# STM32H7A3xxQ register map
File version: 1.0
Registers are 32-bit, read-write, reset 0x0 unless marked. A register's access mark holds for its fields unless they carry their own. Offsets are from the block's base; [hi:lo] are bit positions; lines under a group give offsets from that group.

## DFSDM1_Filter0 — DFSDM module registers
Base 0x40017900
Same registers: DFSDM1_Filter1 0x40017980, DFSDM1_Filter2 0x40017A00, DFSDM1_Filter3 0x40017A80, DFSDM1_Filter4 0x40017B00, DFSDM1_Filter5 0x40017B80, DFSDM1_Filter6 0x40017C00, DFSDM1_Filter7 0x40017C80
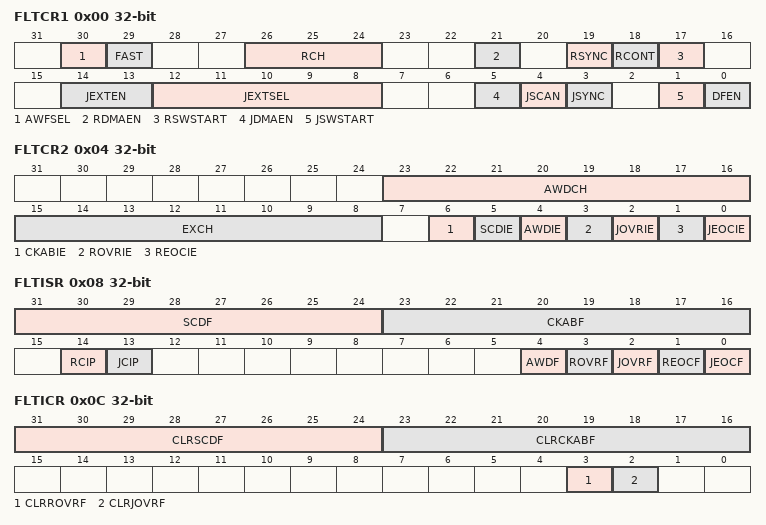
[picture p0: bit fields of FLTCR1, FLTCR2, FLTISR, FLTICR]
0x00 FLTCR1 — DFSDM control register1
  [30] AWFSEL — Analog watchdog fast mode select
  [29] FAST — Fast conversion mode selection
  [26:24] RCH — RCH[2:0] Regular channel selection
  [21] RDMAEN — DMA channel enabled to read data for the regular conversion
  [19] RSYNC — Launch regular conversion synchronously with DFSDMx
  [18] RCONT — Continuous mode selection for regular conversions
  [17] RSWSTART — Software start of a conversion on the regular channel
  [14:13] JEXTEN — JEXTEN[1:0] Trigger enable and trigger edge selection for injected conversions
  [12:8] JEXTSEL — JEXTSEL[4:0]Trigger signal selection for launching injected conversions
  [5] JDMAEN — DMA channel enabled to read data for the injected channel group
  [4] JSCAN — Scanning conversion in continuous mode selection for injected conversions
  [3] JSYNC — Launch an injected conversion synchronously with DFSDMx JSWSTART trigger
  [1] JSWSTART — Start the conversion of the injected group of channels
  [0] DFEN — DFSDM enable
0x04 FLTCR2 — DFSDM control register2
  [23:16] AWDCH — AWDCH[7:0] Analog watchdog channel selection
  [15:8] EXCH — EXCH[7:0] Extreme detector channel selection
  [6] CKABIE — Clock absence interrupt enable
  [5] SCDIE — Short circuit detector interrupt enable
  [4] AWDIE — Analog watchdog interrupt enable
  [3] ROVRIE — Regular data overrun interrupt enable
  [2] JOVRIE — Injected data overrun interrupt enable
  [1] REOCIE — Regular end of conversion interrupt enable
  [0] JEOCIE — Injected end of conversion interrupt enable
0x08 FLTISR — DFSDM interrupt and status register
  [31:24] SCDF — SCDF[7:0] Short circuit detector flag
  [23:16] CKABF — CKABF[7:0] Clock absence flag
  [14] RCIP — Regular conversion in progress status
  [13] JCIP — Injected conversion in progress status
  [4] AWDF — Analog watchdog
  [3] ROVRF — Regular conversion overrun flag
  [2] JOVRF — Injected conversion overrun flag
  [1] REOCF — End of regular conversion flag
  [0] JEOCF — End of injected conversion flag
0x0C FLTICR — DFSDM interrupt flag clear register
  [31:24] CLRSCDF — CLRSCSDF[7:0] Clear the short circuit detector flag
  [23:16] CLRCKABF — CLRCKABF[7:0] Clear the clock absence flag
  [3] CLRROVRF — Clear the regular conversion overrun flag
  [2] CLRJOVRF — Clear the injected conversion overrun flag
0x10 FLTJCHGR — DFSDM injected channel group selection register
  [7:0] JCHG — JCHG[7:0] Injected channel group selection
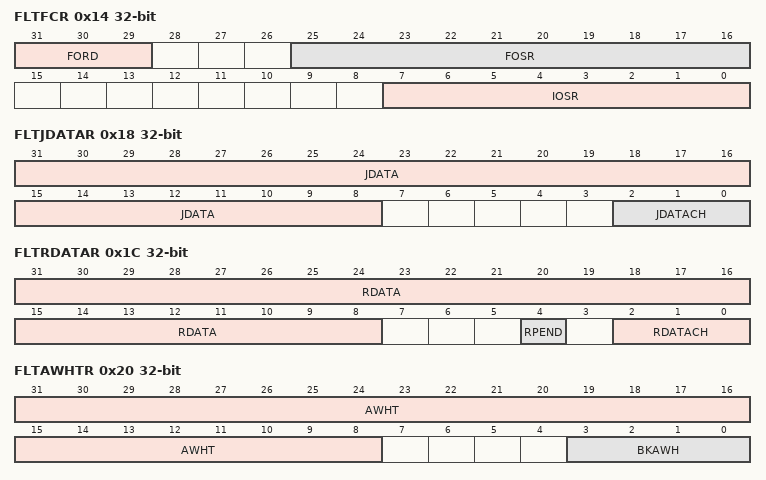
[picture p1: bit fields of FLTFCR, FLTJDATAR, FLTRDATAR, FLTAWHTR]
0x14 FLTFCR — DFSDM filter control register
  [31:29] FORD — FORD[2:0] Sinc filter order
  [25:16] FOSR — FOSR[9:0] Sinc filter oversampling ratio (decimation rate)
  [7:0] IOSR — IOSR[7:0] Integrator oversampling ratio (averaging length)
0x18 FLTJDATAR — DFSDM data register for injected group
  [31:8] JDATA — JDATA[23:0] Injected group conversion data
  [2:0] JDATACH — JDATACH[2:0] Injected channel most recently converted
0x1C FLTRDATAR — DFSDM data register for regular group
  [31:8] RDATA — RDATA[23:0] Regular channel conversion data
  [4] RPEND — RPEND Regular channel pending data
  [2:0] RDATACH — RDATACH[2:0] Regular channel most recently converted
0x20 FLTAWHTR — DFSDM analog watchdog high threshold register
  [31:8] AWHT — AWHT[23:0] Analog watchdog high threshold
  [3:0] BKAWH — BKAWH[3:0] Break signal assignment to analog watchdog high threshold event
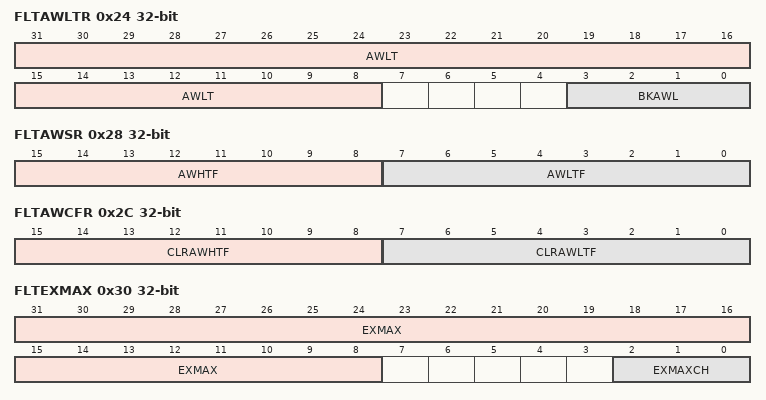
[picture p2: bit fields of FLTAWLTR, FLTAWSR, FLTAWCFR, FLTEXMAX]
0x24 FLTAWLTR — DFSDM analog watchdog low threshold register
  [31:8] AWLT — AWHT[23:0] Analog watchdog low threshold
  [3:0] BKAWL — BKAWL[3:0] Break signal assignment to analog watchdog low threshold event
0x28 FLTAWSR — DFSDM analog watchdog status register
  [15:8] AWHTF — AWHTF[15:8] Analog watchdog high threshold error on given channels
  [7:0] AWLTF — AWLTF[7:0] Analog watchdog low threshold error on given channels
0x2C FLTAWCFR — DFSDM analog watchdog clear flag register
  [15:8] CLRAWHTF — CLRAWHTF[15:8] Clear the Analog watchdog high threshold flag
  [7:0] CLRAWLTF — CLRAWLTF[7:0] Clear the Analog watchdog low threshold flag
0x30 FLTEXMAX — DFSDM extreme detector maximum register
  [31:8] EXMAX — EXMAX[23:0] Extreme detector maximum value
  [2:0] EXMAXCH — EXMAXCH[2:0] Extreme detector maximum data channel
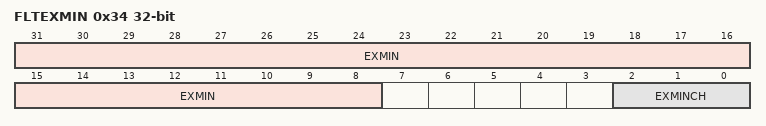
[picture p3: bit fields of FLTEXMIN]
0x34 FLTEXMIN — DFSDM extreme detector minimum register
  [31:8] EXMIN — EXMIN[23:0] Extreme detector minimum value
  [2:0] EXMINCH — EXMINCH[2:0] Extreme detector minimum data channel
0x38 FLTCNVTIMR — DFSDM conversion timer
  [31:4] CNVCNT — CNVCNT[27:0]: 28-bit timer counting conversion time
